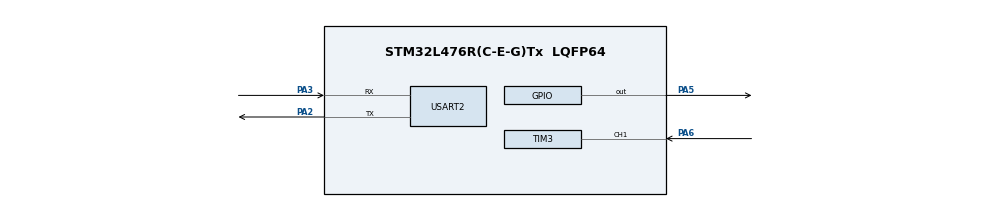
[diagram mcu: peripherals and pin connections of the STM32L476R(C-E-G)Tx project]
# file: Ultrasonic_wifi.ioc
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Mcu.Family=STM32L4
Mcu.Name=STM32L476R(C-E-G)Tx
Mcu.Package=LQFP64
NVIC.PriorityGroup=NVIC_PRIORITYGROUP_4
NVIC.TIM3_IRQn=true\:0\:0\:false\:false\:true\:true\:true\:true
NVIC.USART2_IRQn=true\:0\:0\:false\:false\:true\:true\:true\:true
PA13\ (JTMS-SWDIO).Mode=Serial_Wire
PA13\ (JTMS-SWDIO).Signal=SYS_JTMS-SWDIO
PA14\ (JTCK-SWCLK).Mode=Serial_Wire
PA14\ (JTCK-SWCLK).Signal=SYS_JTCK-SWCLK
PA2.Mode=Asynchronous
PA2.Signal=USART2_TX
PA3.Mode=Asynchronous
PA3.Signal=USART2_RX
PA5.GPIO_Speed=GPIO_SPEED_FREQ_HIGH
PA5.Signal=GPIO_Output
PA6.Signal=S_TIM3_CH1
ProjectManager.HeapSize=0x200
ProjectManager.StackSize=0x400
ProjectManager.TargetToolchain=STM32CubeIDE
RCC.HSE_VALUE=8000000
RCC.HSI_VALUE=16000000
RCC.LSE_VALUE=32768
RCC.MSI_VALUE=4000000
RCC.VCOOutputFreq_Value=32000000
SH.S_TIM3_CH1.0=TIM3_CH1,Input_Capture1_from_TI1
TIM3.Channel-Input_Capture1_from_TI1=TIM_CHANNEL_1
TIM3.Prescaler=79
USART2.VirtualMode-Asynchronous=VM_ASYNC
board=custom

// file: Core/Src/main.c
/* USER CODE BEGIN Header */
/**
  ******************************************************************************
  * @file           : main.c
  * @brief          : Main program body
  ******************************************************************************
  * @attention
  *
  * Copyright (c) 2025 STMicroelectronics.
  * All rights reserved.
  *
  * This software is licensed under terms that can be found in the LICENSE file
  * in the root directory of this software component.
  * If no LICENSE file comes with this software, it is provided AS-IS.
  *
  ******************************************************************************
  */
/* USER CODE END Header */
#include "main.h"

/* USER CODE BEGIN Includes */
#include "ultrasonic.h"
#include "esp_ap_web.h"
/* USER CODE END Includes */

TIM_HandleTypeDef htim3;

UART_HandleTypeDef huart2;

/* USER CODE BEGIN PV */
uint8_t esp_rx_tmp;       // 1-byte UART RX buffer
uint32_t distance_cm = 0; // displayed distance
/* USER CODE END PV */

void SystemClock_Config(void);
static void MX_GPIO_Init(void);
static void MX_TIM3_Init(void);
static void MX_USART2_UART_Init(void);

int main(void)
{
  HAL_Init();
  SystemClock_Config();
  MX_GPIO_Init();
  MX_TIM3_Init();
  MX_USART2_UART_Init();

  /* USER CODE BEGIN 2 --------------------------------------------------------*/

  /* 1) Initialize microsecond delay */
  DWT_Delay_Init();

  /* 2) Initialize Ultrasonic Trigger pin + Timer */
  Ultrasonic_Init(&htim3, TRIG_GPIO_Port, TRIG_Pin);

  /* 3) Start TIM3 Input Capture interrupt */
  HAL_TIM_IC_Start_IT(&htim3, TIM_CHANNEL_1);

  /* 4) Initialize ESP module */
  ESPAP_Init(&huart2);

  /* Start receiving UART bytes */
  HAL_UART_Receive_IT(&huart2, &esp_rx_tmp, 1);

  /* Reset and Configure ESP8266 in AP Mode */
  ESPAP_Reset();
  HAL_Delay(1500);

  ESPAP_SendAT();
  HAL_Delay(500);

  ESPAP_SetAPMode(); // CWMODE=2
  HAL_Delay(500);

  // AP Name = UltrasonicESP, Password = ""
  ESPAP_SetAP("UltrasonicESP", "");
  HAL_Delay(1000);

  ESPAP_EnableMUX();
  HAL_Delay(500);

  ESPAP_StartServer(80);
  HAL_Delay(1000);

  /* USER CODE END 2 ----------------------------------------------------------*/

  while (1)
  {
    /* USER CODE BEGIN WHILE */

    distance_cm = Ultrasonic_Measure();
    if (distance_cm == 0xFFFFFFFF)
      distance_cm = 0;

    ESPAP_UpdateDistance(distance_cm);

    HAL_Delay(300);  // 3 samples per second

    /* USER CODE END WHILE */
  }

}

/* ------------------------------------------------------------- */
/* System Clock Configuration                                    */
/* ------------------------------------------------------------- */
void SystemClock_Config(void)
{
  RCC_OscInitTypeDef RCC_OscInitStruct = {0};
  RCC_ClkInitTypeDef RCC_ClkInitStruct = {0};

  if (HAL_PWREx_ControlVoltageScaling(PWR_REGULATOR_VOLTAGE_SCALE1) != HAL_OK)
    Error_Handler();

  RCC_OscInitStruct.OscillatorType = RCC_OSCILLATORTYPE_MSI;
  RCC_OscInitStruct.MSIState = RCC_MSI_ON;
  RCC_OscInitStruct.MSICalibrationValue = 0;
  RCC_OscInitStruct.MSIClockRange = RCC_MSIRANGE_6;
  RCC_OscInitStruct.PLL.PLLState = RCC_PLL_NONE;
  if (HAL_RCC_OscConfig(&RCC_OscInitStruct) != HAL_OK)
    Error_Handler();

  RCC_ClkInitStruct.ClockType = RCC_CLOCKTYPE_HCLK | RCC_CLOCKTYPE_SYSCLK
                              | RCC_CLOCKTYPE_PCLK1 | RCC_CLOCKTYPE_PCLK2;
  RCC_ClkInitStruct.SYSCLKSource = RCC_SYSCLKSOURCE_MSI;
  RCC_ClkInitStruct.AHBCLKDivider = RCC_SYSCLK_DIV1;
  RCC_ClkInitStruct.APB1CLKDivider = RCC_HCLK_DIV1;
  RCC_ClkInitStruct.APB2CLKDivider = RCC_HCLK_DIV1;

  if (HAL_RCC_ClockConfig(&RCC_ClkInitStruct, FLASH_LATENCY_0) != HAL_OK)
    Error_Handler();
}

/* ------------------------------------------------------------- */
/* TIM3 Initialization                                            */
/* ------------------------------------------------------------- */
static void MX_TIM3_Init(void)
{
  TIM_MasterConfigTypeDef sMasterConfig = {0};
  TIM_IC_InitTypeDef sConfigIC = {0};

  htim3.Instance = TIM3;
  htim3.Init.Prescaler = 79;     // 1MHz = 1µs tick
  htim3.Init.CounterMode = TIM_COUNTERMODE_UP;
  htim3.Init.Period = 65535;
  htim3.Init.ClockDivision = TIM_CLOCKDIVISION_DIV1;
  htim3.Init.AutoReloadPreload = TIM_AUTORELOAD_PRELOAD_DISABLE;

  if (HAL_TIM_IC_Init(&htim3) != HAL_OK)
    Error_Handler();

  sMasterConfig.MasterOutputTrigger = TIM_TRGO_RESET;
  sMasterConfig.MasterSlaveMode     = TIM_MASTERSLAVEMODE_DISABLE;
  HAL_TIMEx_MasterConfigSynchronization(&htim3, &sMasterConfig);

  sConfigIC.ICPolarity  = TIM_INPUTCHANNELPOLARITY_RISING;
  sConfigIC.ICSelection = TIM_ICSELECTION_DIRECTTI;
  sConfigIC.ICPrescaler = TIM_ICPSC_DIV1;
  sConfigIC.ICFilter    = 0;

  if (HAL_TIM_IC_ConfigChannel(&htim3, &sConfigIC, TIM_CHANNEL_1) != HAL_OK)
    Error_Handler();
}

/* ------------------------------------------------------------- */
/* UART2 Initialization                                           */
/* ------------------------------------------------------------- */
static void MX_USART2_UART_Init(void)
{
  huart2.Instance = USART2;
  huart2.Init.BaudRate   = 115200;
  huart2.Init.WordLength = UART_WORDLENGTH_8B;
  huart2.Init.StopBits   = UART_STOPBITS_1;
  huart2.Init.Parity     = UART_PARITY_NONE;
  huart2.Init.Mode       = UART_MODE_TX_RX;
  huart2.Init.HwFlowCtl  = UART_HWCONTROL_NONE;
  huart2.Init.OverSampling = UART_OVERSAMPLING_16;
  huart2.Init.OneBitSampling = UART_ONE_BIT_SAMPLE_DISABLE;
  huart2.AdvancedInit.AdvFeatureInit = UART_ADVFEATURE_NO_INIT;

  if (HAL_UART_Init(&huart2) != HAL_OK)
    Error_Handler();
}

/* ------------------------------------------------------------- */
/* GPIO Initialization                                            */
/* ------------------------------------------------------------- */
static void MX_GPIO_Init(void)
{
  GPIO_InitTypeDef GPIO_InitStruct = {0};
  __HAL_RCC_GPIOA_CLK_ENABLE();

  HAL_GPIO_WritePin(GPIOA, GPIO_PIN_5, GPIO_PIN_RESET);

  /* TRIG Pin: PA5 */
  GPIO_InitStruct.Pin = GPIO_PIN_5;
  GPIO_InitStruct.Mode = GPIO_MODE_OUTPUT_PP;
  GPIO_InitStruct.Pull = GPIO_NOPULL;
  GPIO_InitStruct.Speed = GPIO_SPEED_FREQ_HIGH;
  HAL_GPIO_Init(GPIOA, &GPIO_InitStruct);
}

/* ------------------------------------------------------------- */
/* Callback handlers                                             */
/* ------------------------------------------------------------- */
void HAL_TIM_IC_CaptureCallback(TIM_HandleTypeDef *htim)
{
  if (htim->Instance == TIM3)
    Ultrasonic_IC_CaptureCallback(htim);
}

void HAL_UART_RxCpltCallback(UART_HandleTypeDef *huart)
{
  if (huart == &huart2)
  {
    ESPAP_HandleUARTByte(esp_rx_tmp);
    HAL_UART_Receive_IT(&huart2, &esp_rx_tmp, 1);
  }
}

/* ------------------------------------------------------------- */
void Error_Handler(void)
{
  __disable_irq();
  while (1) {}
}
